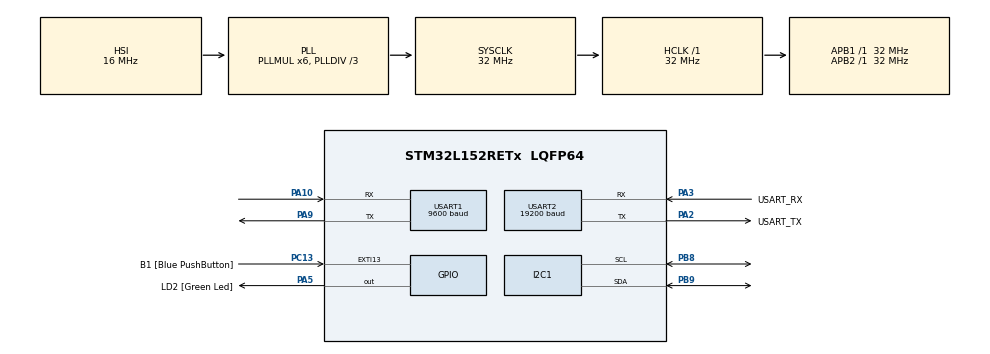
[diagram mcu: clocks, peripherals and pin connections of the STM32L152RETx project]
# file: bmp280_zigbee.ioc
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Mcu.Family=STM32L1
Mcu.Name=STM32L152RETx
Mcu.Package=LQFP64
NVIC.PriorityGroup=NVIC_PRIORITYGROUP_0
PA10.Mode=Asynchronous
PA10.Signal=USART1_RX
PA13.GPIO_Label=TMS
PA13.Mode=Serial_Wire
PA13.Signal=SYS_JTMS-SWDIO
PA14.GPIO_Label=TCK
PA14.Mode=Serial_Wire
PA14.Signal=SYS_JTCK-SWCLK
PA2.GPIO_Label=USART_TX
PA2.Mode=Asynchronous
PA2.Signal=USART2_TX
PA3.GPIO_Label=USART_RX
PA3.Mode=Asynchronous
PA3.Signal=USART2_RX
PA5.GPIO_Label=LD2 [Green Led]
PA5.Signal=GPIO_Output
PA9.Mode=Asynchronous
PA9.Signal=USART1_TX
PB3.GPIO_Label=SWO
PB3.Signal=SYS_JTDO-TRACESWO
PB8.Mode=I2C
PB8.Signal=I2C1_SCL
PB9.Mode=I2C
PB9.Signal=I2C1_SDA
PC13-WKUP2.GPIO_Label=B1 [Blue PushButton]
PC13-WKUP2.Signal=GPXTI13
PC14-OSC32_IN.Mode=LSE-External-Oscillator
PC14-OSC32_IN.Signal=RCC_OSC32_IN
PC15-OSC32_OUT.Mode=LSE-External-Oscillator
PC15-OSC32_OUT.Signal=RCC_OSC32_OUT
PH0-OSC_IN.Mode=HSE-External-Clock-Source
PH0-OSC_IN.Signal=RCC_OSC_IN
PH1-OSC_OUT.Signal=RCC_OSC_OUT
ProjectManager.HeapSize=0x200
ProjectManager.StackSize=0x400
ProjectManager.TargetToolchain=STM32CubeIDE
RCC.48MHZClocksFreq_Value=48000000
RCC.AHBFreq_Value=32000000
RCC.APB1Freq_Value=32000000
RCC.APB1TimFreq_Value=32000000
RCC.APB2Freq_Value=32000000
RCC.APB2TimFreq_Value=32000000
RCC.HCLKFreq_Value=32000000
RCC.HSE_VALUE=8000000
RCC.HSI_VALUE=16000000
RCC.MSI_VALUE=2097000
RCC.PLLDIV=RCC_PLL_DIV3
RCC.PLLMUL=RCC_PLL_MUL6
RCC.RTCClockSelectionVirtual=RCC_RTCCLKSOURCE_LSE
RCC.SYSCLKFreq_VALUE=32000000
RCC.SYSCLKSource=RCC_SYSCLKSOURCE_PLLCLK
RCC.USBOutput=48000000
RCC.VCOOutputFreq_Value=96000000
USART1.BaudRate=9600
USART1.VirtualMode=VM_ASYNC
USART2.BaudRate=19200
USART2.VirtualMode=VM_ASYNC
board=NUCLEO-L152RE

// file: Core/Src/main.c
/* USER CODE BEGIN Header */
/**
  ******************************************************************************
  * @file           : main.c
  * @brief          : Main program body
  ******************************************************************************
  * @attention
  *
  * Copyright (c) 2023 STMicroelectronics.
  * All rights reserved.
  *
  * This software is licensed under terms that can be found in the LICENSE file
  * in the root directory of this software component.
  * If no LICENSE file comes with this software, it is provided AS-IS.
  *
  ******************************************************************************
  */
/* USER CODE END Header */
#include "main.h"
#include "i2c.h"
#include "usart.h"
#include "gpio.h"
#include "bmp280.h"
#include <stdint.h>
#include<stdio.h>
#include<lib_lcd.h>

static rgb_lcd var;
/* USER CODE BEGIN Includes */
BMP280_HandleTypedef bmp280;

float pressure, temperature, humidity;

uint16_t size;
uint8_t Data[256];

/* USER CODE END Includes */

void SystemClock_Config(void);

int main(void)
{

  /* MCU Configuration--------------------------------------------------------*/

  /* Reset of all peripherals, Initializes the Flash interface and the Systick. */
  HAL_Init();

  /* Configure the system clock */
  SystemClock_Config();

  /* Initialize all configured peripherals */
  MX_GPIO_Init();
  MX_USART2_UART_Init();
  MX_I2C1_Init();
  MX_USART1_UART_Init();
  /* USER CODE BEGIN 2 */
  bmp280_init_default_params(&bmp280.params);
  bmp280.addr = BMP280_I2C_ADDRESS_1;
  bmp280.i2c = &hi2c1;
  /* USER CODE END 2 */

  /* Infinite loop */
  /* USER CODE BEGIN WHILE */
  bmp280_init(&bmp280, &bmp280.params);
  while (1)
   {
     /* USER CODE END WHILE */
 	  while (!bmp280_read_float(&bmp280, &temperature, &pressure, &humidity)) {
 	  			size = sprintf((char *)Data,"Temperature/pressure reading failed\n\r");
 	  			HAL_UART_Transmit(&huart2, Data, size, 1000);
 	  			HAL_Delay(2000);
 	  		}
 	  pressure=pressure/100.;

 	  size = sprintf((char *)Data,"Temp: %.1f C", temperature);
 	 // HAL_UART_Transmit(&huart2, Data, size, 1000);
 	  HAL_UART_Transmit(&huart1, Data, size, 1000);

 	  lcd_position(&hi2c1,0,0);
 	 // lcd_print(&hi2c1,"Temp:  ");
 	//  lcd_position(&hi2c1,6,0);
 	  lcd_print(&hi2c1,Data);

 	  size = sprintf((char *)Data,"Pres: %.1f hPa", pressure);
 	//  HAL_UART_Transmit(&huart2, Data, size, 1000);
 	  HAL_UART_Transmit(&huart1, Data, size, 1000);

 	  lcd_position(&hi2c1,0,1);
 	 // lcd_print(&hi2c1,"Pres: ");
 	  //lcd_position(&hi2c1,6,1);
 	  lcd_print(&hi2c1,Data);
 	 // size = sprintf((char *)Data,", Humidity: %.2f\n\r", humidity);
 	 // HAL_UART_Transmit(&huart2, Data, size, 1000);
     /* USER CODE BEGIN 3 */
 	  HAL_Delay(2000);
   }
   /* USER CODE END 3 */
 }

 /**
   * @brief System Clock Configuration
  * @retval None
  */
void SystemClock_Config(void)
{
  RCC_OscInitTypeDef RCC_OscInitStruct = {0};
  RCC_ClkInitTypeDef RCC_ClkInitStruct = {0};

  /** Configure the main internal regulator output voltage
  */
  __HAL_PWR_VOLTAGESCALING_CONFIG(PWR_REGULATOR_VOLTAGE_SCALE1);

  /** Initializes the RCC Oscillators according to the specified parameters
  * in the RCC_OscInitTypeDef structure.
  */
  RCC_OscInitStruct.OscillatorType = RCC_OSCILLATORTYPE_HSI;
  RCC_OscInitStruct.HSIState = RCC_HSI_ON;
  RCC_OscInitStruct.HSICalibrationValue = RCC_HSICALIBRATION_DEFAULT;
  RCC_OscInitStruct.PLL.PLLState = RCC_PLL_ON;
  RCC_OscInitStruct.PLL.PLLSource = RCC_PLLSOURCE_HSI;
  RCC_OscInitStruct.PLL.PLLMUL = RCC_PLL_MUL6;
  RCC_OscInitStruct.PLL.PLLDIV = RCC_PLL_DIV3;
  if (HAL_RCC_OscConfig(&RCC_OscInitStruct) != HAL_OK)
  {
    Error_Handler();
  }

  /** Initializes the CPU, AHB and APB buses clocks
  */
  RCC_ClkInitStruct.ClockType = RCC_CLOCKTYPE_HCLK|RCC_CLOCKTYPE_SYSCLK
                              |RCC_CLOCKTYPE_PCLK1|RCC_CLOCKTYPE_PCLK2;
  RCC_ClkInitStruct.SYSCLKSource = RCC_SYSCLKSOURCE_PLLCLK;
  RCC_ClkInitStruct.AHBCLKDivider = RCC_SYSCLK_DIV1;
  RCC_ClkInitStruct.APB1CLKDivider = RCC_HCLK_DIV1;
  RCC_ClkInitStruct.APB2CLKDivider = RCC_HCLK_DIV1;

  if (HAL_RCC_ClockConfig(&RCC_ClkInitStruct, FLASH_LATENCY_1) != HAL_OK)
  {
    Error_Handler();
  }
}

void Error_Handler(void)
{
  __disable_irq();
  while (1)
  {
  }
}
